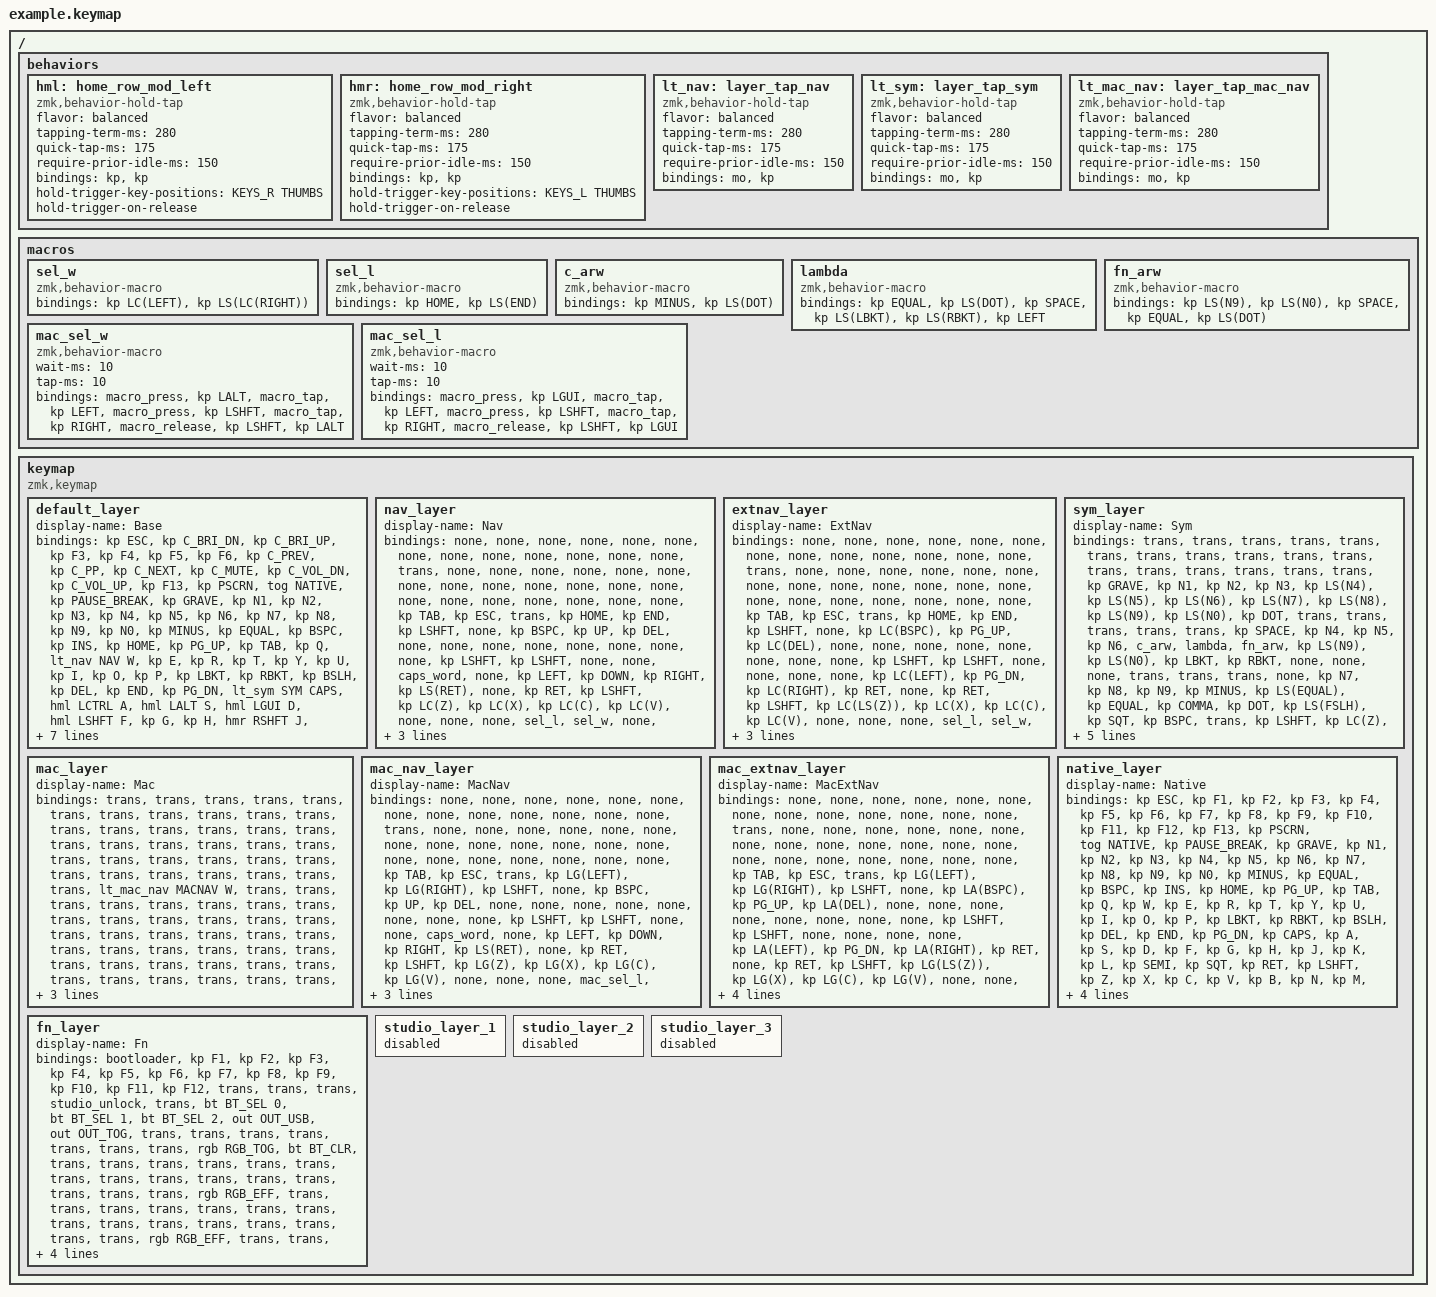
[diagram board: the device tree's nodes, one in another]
/*
 * Wobkey Crush 80 — ZMK keymap (Home Row Mods + Layers)
 *
 * Mirrors the kanata configuration at ~/.config/DOTFILES/keybindings/kanata/
 * Primary target: Linux/Windows (macOS compatible via home row GUI mod)
 *
 * Layer 0: Base — HRM (CAGS), media F-row, W(hold)=Nav, Caps(hold)=Sym, '(hold)=Sym
 * Layer 1: Nav — IJKL arrows, editing (hold W)
 * Layer 2: ExtNav — Word-jump, PgUp/PgDn (hold Space while in Nav)
 * Layer 3: Sym — Numbers left, punctuation right (hold Caps or ')
 * Layer 4-6: Mac / MacNav / MacExtNav — macOS shortcuts, toggled by Fn+M
 * Layer 7: Native — Full passthrough, toggled by ScrLk
 * Layer 8: Fn — F1-F12, BT profiles, RGB, output toggle (top layer)
 * Layer 9-11: reserved, for layers added in ZMK Studio (must stay last)
 *
 * Bottom row (base):
 *   LCtrl  LGui  [Shift]  Space  [Tab]  Fn  RCtrl  |  Left Down Right
 *   LAlt position = Shift (thumb), RAlt position = Tab (thumb)
 *
 * Fn shortcuts:
 *   BT profile 1/2/3 = Fn+1/2/3
 *   USB output = Fn+4, USB/BT toggle = Fn+5
 *   BT clear = Fn+Ins
 *   Bootloader = Fn+Esc, ZMK Studio unlock = Fn+Pause
 */

/* Build every ZMK behavior, not only the ones this file references, so that
 * ZMK Studio and VIA can assign them (&to, &lt, &mt, &sk, ...). The
 * studio-rpc-usb-uart snippet normally defines this; the Bluetooth Studio
 * transport used here does not. Must come before behaviors.dtsi. */
#define ZMK_BEHAVIORS_KEEP_ALL

#include <behaviors.dtsi>
#include <dt-bindings/zmk/keys.h>
#include <dt-bindings/zmk/bt.h>
#include <dt-bindings/zmk/outputs.h>
#include <dt-bindings/zmk/rgb.h>
#include <rainy_rgb.dtsi>
#include <via_macro.dtsi>
#include <dt-bindings/rainy_rgb.h>

/* Layer indices: the order of the layer nodes in the keymap below. */
#define BASE      0
#define NAV       1
#define EXTNAV    2
#define SYM       3
#define MAC       4
#define MACNAV    5
#define MACEXTNAV 6
#define NATIVE    7
#define FN        8

/*
 * Key position indices for hold-trigger-key-positions (bilateral HRM).
 * Derived from the matrix transform in crush80.dts (88 positions, 0-indexed).
 *
 * Row 0 (F-row):     0-16    (ESC F1-F12 F13 PrtSc ScrLk Pause)
 * Row 1 (numbers):   17-33   (` 1-0 - = Bspc | Ins Home PgUp)
 * Row 2 (QWERTY):    34-50   (Tab Q-P [ ] \ | Del End PgDn)
 * Row 3 (home):      51-63   (Caps A-L ; ' Enter)
 * Row 4 (shift):     64-76   (LSft Z-/ RSft Up)
 * Row 5 (bottom):    77-87   (LCtl LGui LAlt Spc RAlt Fn RGui RCtl | Left Down Right)
 */

/* Left hand: up to the T / G / B / 5 / F5 column */
#define KEYS_L \
    0  1  2  3  4  5 \
    17 18 19 20 21 22 \
    34 35 36 37 38 39 \
    51 52 53 54 55 56 \
    64 65 66 67 68 69 \
    77 78

/* Right hand: from the Y / H / N / 6 / F6 column, plus nav cluster and arrows */
#define KEYS_R \
    6  7  8  9  10 11 12 13 14 15 16 \
    23 24 25 26 27 28 29 30 31 32 33 \
    40 41 42 43 44 45 46 47 48 49 50 \
    57 58 59 60 61 62 63 \
    70 71 72 73 74 75 76 \
    82 83 84 85 86 87

/* Thumb keys: LAlt position, Space, RAlt position */
#define THUMBS 79 80 81

/ {
	behaviors {
		/*
		 * Home Row Mods — left hand.
		 * Only triggers hold when a right-hand key is pressed.
		 */
		hml: home_row_mod_left {
			compatible = "zmk,behavior-hold-tap";
			#binding-cells = <2>;
			flavor = "balanced";
			tapping-term-ms = <280>;
			quick-tap-ms = <175>;
			require-prior-idle-ms = <150>;
			bindings = <&kp>, <&kp>;
			hold-trigger-key-positions = <KEYS_R THUMBS>;
			hold-trigger-on-release;
		};

		/*
		 * Home Row Mods — right hand.
		 * Only triggers hold when a left-hand key is pressed.
		 */
		hmr: home_row_mod_right {
			compatible = "zmk,behavior-hold-tap";
			#binding-cells = <2>;
			flavor = "balanced";
			tapping-term-ms = <280>;
			quick-tap-ms = <175>;
			require-prior-idle-ms = <150>;
			bindings = <&kp>, <&kp>;
			hold-trigger-key-positions = <KEYS_L THUMBS>;
			hold-trigger-on-release;
		};

		/*
		 * Layer-tap for Nav (hold W).
		 * Uses balanced flavor with same timings as HRM.
		 */
		lt_nav: layer_tap_nav {
			compatible = "zmk,behavior-hold-tap";
			#binding-cells = <2>;
			flavor = "balanced";
			tapping-term-ms = <280>;
			quick-tap-ms = <175>;
			require-prior-idle-ms = <150>;
			bindings = <&mo>, <&kp>;
		};

		/*
		 * Layer-tap for Sym (hold Caps or Apostrophe).
		 * Caps: tap=CAPS, hold=Sym. Apostrophe: tap=SQT, hold=Sym.
		 */
		lt_sym: layer_tap_sym {
			compatible = "zmk,behavior-hold-tap";
			#binding-cells = <2>;
			flavor = "balanced";
			tapping-term-ms = <280>;
			quick-tap-ms = <175>;
			require-prior-idle-ms = <150>;
			bindings = <&mo>, <&kp>;
		};

		/*
		 * Layer-tap for MacNav (hold W in Mac mode).
		 * Same timings as lt_nav but activates MACNAV.
		 */
		lt_mac_nav: layer_tap_mac_nav {
			compatible = "zmk,behavior-hold-tap";
			#binding-cells = <2>;
			flavor = "balanced";
			tapping-term-ms = <280>;
			quick-tap-ms = <175>;
			require-prior-idle-ms = <150>;
			bindings = <&mo>, <&kp>;
		};
	};

	macros {
		/*
		 * Select Word: Ctrl+Left then Shift+Ctrl+Right (Linux/Windows)
		 */
		sel_w: sel_w {
			compatible = "zmk,behavior-macro";
			#binding-cells = <0>;
			bindings = <&kp LC(LEFT) &kp LS(LC(RIGHT))>;
		};

		/*
		 * Select Line: Home then Shift+End (Linux/Windows)
		 */
		sel_l: sel_l {
			compatible = "zmk,behavior-macro";
			#binding-cells = <0>;
			bindings = <&kp HOME &kp LS(END)>;
		};

		/*
		 * C-style arrow: ->
		 */
		c_arw: c_arw {
			compatible = "zmk,behavior-macro";
			#binding-cells = <0>;
			bindings = <&kp MINUS &kp LS(DOT)>;
		};

		/*
		 * Lambda body: => {} with cursor inside braces
		 */
		lambda: lambda {
			compatible = "zmk,behavior-macro";
			#binding-cells = <0>;
			bindings = <&kp EQUAL &kp LS(DOT) &kp SPACE &kp LS(LBKT) &kp LS(RBKT) &kp LEFT>;
		};

		/*
		 * Arrow function start: () =>
		 */
		fn_arw: fn_arw {
			compatible = "zmk,behavior-macro";
			#binding-cells = <0>;
			bindings = <&kp LS(N9) &kp LS(N0) &kp SPACE &kp EQUAL &kp LS(DOT)>;
		};

		/*
		 * Mac Select Word: Option+Left then Shift+Option+Right
		 */
		mac_sel_w: mac_sel_w {
			compatible = "zmk,behavior-macro";
			#binding-cells = <0>;
			wait-ms = <10>;
			tap-ms = <10>;
			bindings
				= <&macro_press &kp LALT>
				, <&macro_tap &kp LEFT>
				, <&macro_press &kp LSHFT>
				, <&macro_tap &kp RIGHT>
				, <&macro_release &kp LSHFT &kp LALT>
				;
		};

		/*
		 * Mac Select Line: Cmd+Left then Shift+Cmd+Right
		 */
		mac_sel_l: mac_sel_l {
			compatible = "zmk,behavior-macro";
			#binding-cells = <0>;
			wait-ms = <10>;
			tap-ms = <10>;
			bindings
				= <&macro_press &kp LGUI>
				, <&macro_tap &kp LEFT>
				, <&macro_press &kp LSHFT>
				, <&macro_tap &kp RIGHT>
				, <&macro_release &kp LSHFT &kp LGUI>
				;
		};
	};

	keymap {
		compatible = "zmk,keymap";

		/*
		 * Layer 0: Base
		 *
		 * ┌───┬───┬───┬───┬───┬───┬───┬───┬───┬───┬───┬───┬───┬───┬───┬───┐
		 * │ESC│BDn│BUp│F3 │F4 │F5 │F6 │Prv│P/P│Nxt│Mut│VDn│VUp│PSc│Tog│Pse│
		 * ├───┼───┼───┼───┼───┼───┼───┼───┼───┼───┼───┼───┼───┼───┼───┼───┤
		 * │ ` │ 1 │ 2 │ 3 │ 4 │ 5 │ 6 │ 7 │ 8 │ 9 │ 0 │ - │ = │Bsp│Ins│Hom│PUp│
		 * ├───┼───┼───┼───┼───┼───┼───┼───┼───┼───┼───┼───┼───┼───┼───┼───┤
		 * │Tab│ Q │W/N│ E │ R │ T │ Y │ U │ I │ O │ P │ [ │ ] │ \ │Del│End│PDn│
		 * ├───┼───┼───┼───┼───┼───┼───┼───┼───┼───┼───┼───┼───┼───┼───┼───┤
		 * │Sym│A/C│S/A│D/G│F/S│ G │ H │J/S│K/G│L/A│;/C│Sym│Ent│
		 * ├───┼───┼───┼───┼───┼───┼───┼───┼───┼───┼───┼───┼───────┼───┤
		 * │LSf│ Z │ X │ C │ V │ B │ N │ M │ , │ . │ / │RSf│ ↑ │
		 * ├───┼───┼───┼───────────────────────────┼───┼───┼───┼───┼───┼───┤
		 * │LCt│LGu│Sft│      Space       │Tab│ Fn│RCt│ ← │ ↓ │ → │
		 * └───┴───┴───┴───────────────────┴───┴───┴───┴───┴───┴───┘
		 */
		default_layer {
			display-name = "Base";
			bindings = <
				/* Row 0: F-row (media keys, ScrLk=toggle native) */
				&kp ESC       &kp C_BRI_DN  &kp C_BRI_UP  &kp F3        &kp F4
				&kp F5        &kp F6        &kp C_PREV    &kp C_PP
				&kp C_NEXT    &kp C_MUTE    &kp C_VOL_DN  &kp C_VOL_UP  &kp F13
				&kp PSCRN     &tog NATIVE   &kp PAUSE_BREAK
				/* Row 1: number row + nav cluster */
				&kp GRAVE     &kp N1        &kp N2        &kp N3        &kp N4
				&kp N5        &kp N6        &kp N7        &kp N8        &kp N9
				&kp N0        &kp MINUS     &kp EQUAL     &kp BSPC
				&kp INS       &kp HOME      &kp PG_UP
				/* Row 2: QWERTY + nav cluster (W = tap W / hold Nav) */
				&kp TAB       &kp Q         &lt_nav NAV W &kp E         &kp R
				&kp T         &kp Y         &kp U         &kp I         &kp O
				&kp P         &kp LBKT      &kp RBKT      &kp BSLH
				&kp DEL       &kp END       &kp PG_DN
				/* Row 3: home row (HRM: A=Ctrl, S=Alt, D=Gui, F=Shift / J=Shift, K=Gui, L=Alt, ;=Ctrl) */
				&lt_sym SYM CAPS &hml LCTRL A &hml LALT S &hml LGUI D &hml LSHFT F
				&kp G         &kp H         &hmr RSHFT J  &hmr RGUI K   &hmr RALT L
				&hmr RCTRL SEMI &lt_sym SYM SQT           &kp RET
				/* Row 4: shift row */
				&kp LSHFT                   &kp Z         &kp X         &kp C
				&kp V         &kp B         &kp N         &kp M         &kp COMMA
				&kp DOT       &kp FSLH                    &kp RSHFT     &kp UP
				/* Row 5: bottom row (LAlt=Shift, RAlt=Tab) */
				&kp LCTRL     &kp LGUI      &kp LSHFT                   &kp SPACE
				&kp TAB       &mo FN  &kp RGUI        &kp RCTRL
				&kp LEFT      &kp DOWN      &kp RIGHT
			>;
		};

		/*
		 * Layer 1: Nav (hold W)
		 * Right hand: IJKL arrows, U=Bspc, O=Del, ;=Shift+Enter
		 * Left hand: editing (Undo/Cut/Copy/Paste), E=Home, R=End, T/A/S=Shift
		 * G = Caps Word (auto-deactivates on space/punctuation)
		 */
		nav_layer {
			display-name = "Nav";
			bindings = <
				/* Row 0: blocked */
				&none         &none         &none         &none         &none
				&none         &none         &none         &none
				&none         &none         &none         &none  &trans
				&none         &none         &none
				/* Row 1: blocked */
				&none         &none         &none         &none         &none
				&none         &none         &none         &none         &none
				&none         &none         &none         &none
				&none         &none         &none
				/* Row 2: Tab, Esc, (W held), Home, End, Shift, _, Bspc, Up, Del */
				&kp TAB       &kp ESC       &trans        &kp HOME      &kp END
				&kp LSHFT     &none         &kp BSPC      &kp UP        &kp DEL
				&none         &none         &none         &none
				&none         &none         &none
				/* Row 3: _, Shift, Shift, _, _, CapsWord, _, Left, Down, Right, Shift+Enter */
				&none         &kp LSHFT     &kp LSHFT     &none         &none
				&caps_word    &none         &kp LEFT      &kp DOWN      &kp RIGHT
				&kp LS(RET)   &none                       &kp RET
				/* Row 4: Shift, Undo, Cut, Copy, Paste, _, _, _, SelLine, SelWord */
				&kp LSHFT                   &kp LC(Z)     &kp LC(X)     &kp LC(C)
				&kp LC(V)     &none         &none         &none         &sel_l
				&sel_w        &none                       &kp RSHFT     &trans
				/* Row 5: pass mods through, Space=ExtNav */
				&kp LCTRL     &kp LGUI      &kp LALT                    &mo EXTNAV
				&trans        &trans  &trans        &kp RCTRL
				&trans        &trans        &trans
			>;
		};

		/*
		 * Layer 2: ExtNav (hold Space while in Nav)
		 * Like Nav but word-level: J/L=word jump, I=PgUp, K=PgDn, U/O=word delete
		 * Z=Redo (Ctrl+Shift+Z on Linux/Win)
		 */
		extnav_layer {
			display-name = "ExtNav";
			bindings = <
				/* Row 0: blocked */
				&none         &none         &none         &none         &none
				&none         &none         &none         &none
				&none         &none         &none         &none  &trans
				&none         &none         &none
				/* Row 1: blocked */
				&none         &none         &none         &none         &none
				&none         &none         &none         &none         &none
				&none         &none         &none         &none
				&none         &none         &none
				/* Row 2: Tab, Esc, _, Home, End, Shift, _, WordBspc, PgUp, WordDel */
				&kp TAB       &kp ESC       &trans        &kp HOME      &kp END
				&kp LSHFT     &none         &kp LC(BSPC)  &kp PG_UP     &kp LC(DEL)
				&none         &none         &none         &none
				&none         &none         &none
				/* Row 3: _, Shift, Shift, _, _, _, _, WordLeft, PgDn, WordRight, Enter */
				&none         &kp LSHFT     &kp LSHFT     &none         &none
				&none         &none         &kp LC(LEFT)  &kp PG_DN     &kp LC(RIGHT)
				&kp RET       &none                       &kp RET
				/* Row 4: Shift, Redo, Cut, Copy, Paste, _, _, _, SelLine, SelWord */
				&kp LSHFT                   &kp LC(LS(Z)) &kp LC(X)     &kp LC(C)
				&kp LC(V)     &none         &none         &none         &sel_l
				&sel_w        &none                       &kp RSHFT     &trans
				/* Row 5: mods pass through, Space is held (layer active) */
				&kp LCTRL     &kp LGUI      &kp LALT                    &none
				&trans        &trans  &trans        &kp RCTRL
				&trans        &trans        &trans
			>;
		};

		/*
		 * Layer 3: Sym (hold Caps or Apostrophe)
		 * Left: numbers (456 top, 789 home, 0. bottom) + coding macros
		 * Right: brackets, punctuation, operators
		 * Space = Shift (for capitals without releasing layer key)
		 */
		sym_layer {
			display-name = "Sym";
			bindings = <
				/* Row 0: pass through */
				&trans        &trans        &trans        &trans        &trans
				&trans        &trans        &trans        &trans
				&trans        &trans        &trans        &trans  &trans
				&trans        &trans        &trans
				/* Row 1: number row symbols (` 1 2 3 $ % ^ & * ( ) . = _) */
				&kp GRAVE     &kp N1        &kp N2        &kp N3        &kp LS(N4)
				&kp LS(N5)    &kp LS(N6)    &kp LS(N7)    &kp LS(N8)    &kp LS(N9)
				&kp LS(N0)    &kp DOT       &trans        &trans
				&trans        &trans        &trans
				/* Row 2: left=4,5,6,->,lambda | right=() =>, (, ), [, ] */
				&kp SPACE     &kp N4        &kp N5        &kp N6        &c_arw
				&lambda       &fn_arw       &kp LS(N9)    &kp LS(N0)    &kp LBKT
				&kp RBKT      &none         &none         &none
				&trans        &trans        &trans
				/* Row 3: left=_,7,8,9,-,+ | right==,comma,dot,?,',bspc */
				&none         &kp N7        &kp N8        &kp N9        &kp MINUS
				&kp LS(EQUAL) &kp EQUAL     &kp COMMA     &kp DOT       &kp LS(FSLH)
				&kp SQT       &kp BSPC                    &trans
				/* Row 4: Shift, Undo, 0, dot, \, |, /, _, _, _, _ */
				&kp LSHFT                   &kp LC(Z)     &kp N0        &kp DOT
				&kp BSLH      &kp LS(BSLH)  &kp FSLH      &none         &none
				&none         &none                       &kp RSHFT     &trans
				/* Row 5: pass mods, Space=Shift, right thumb=0,dot */
				&kp LCTRL     &kp LGUI      &trans                      &kp LSHFT
				&kp N0        &kp DOT  &trans       &kp RCTRL
				&trans        &trans        &trans
			>;
		};

		/*
		 * Layer 4: Mac (toggle Fn+M)
		 * Transparent: same as Base except W-hold activates MacNav instead of Nav.
		 * (Must stay transparent, or it hides Base's HRM and Sym keys.)
		 */
		mac_layer {
			display-name = "Mac";
			bindings = <
				/* Row 0 */
				&trans        &trans        &trans        &trans        &trans
				&trans        &trans        &trans        &trans        &trans
				&trans        &trans        &trans  &trans        &trans        &trans
				&trans
				/* Row 1 */
				&trans        &trans        &trans        &trans        &trans
				&trans        &trans        &trans        &trans        &trans
				&trans        &trans        &trans        &trans        &trans
				&trans        &trans
				/* Row 2: only W-hold differs (MacNav) */
				&trans        &trans        &lt_mac_nav MACNAV W  &trans        &trans
				&trans        &trans        &trans        &trans        &trans
				&trans        &trans        &trans        &trans        &trans
				&trans        &trans
				/* Row 3 */
				&trans        &trans        &trans        &trans        &trans
				&trans        &trans        &trans        &trans        &trans
				&trans        &trans        &trans
				/* Row 4 */
				&trans        &trans        &trans        &trans        &trans
				&trans        &trans        &trans        &trans        &trans
				&trans        &trans        &trans
				/* Row 5 */
				&trans        &trans        &trans        &trans        &trans
				&trans  &trans        &trans        &trans        &trans        &trans
			>;
		};

		/*
		 * Layer 5: MacNav (hold W in Mac mode)
		 * Same as Nav but with macOS shortcuts:
		 *   Home/End → Cmd+Left/Right, Cut/Copy/Paste → Cmd+X/C/V
		 *   Select Word/Line → Option/Cmd macros
		 */
		mac_nav_layer {
			display-name = "MacNav";
			bindings = <
				/* Row 0: blocked */
				&none         &none         &none         &none         &none
				&none         &none         &none         &none
				&none         &none         &none         &none  &trans
				&none         &none         &none
				/* Row 1: blocked */
				&none         &none         &none         &none         &none
				&none         &none         &none         &none         &none
				&none         &none         &none         &none
				&none         &none         &none
				/* Row 2: Tab, Esc, (W held), Cmd+Left, Cmd+Right, Shift */
				&kp TAB       &kp ESC       &trans        &kp LG(LEFT)  &kp LG(RIGHT)
				&kp LSHFT     &none         &kp BSPC      &kp UP        &kp DEL
				&none         &none         &none         &none
				&none         &none         &none
				/* Row 3: _, Shift, Shift, _, _, CapsWord, _, Left, Down, Right, Shift+Enter */
				&none         &kp LSHFT     &kp LSHFT     &none         &none
				&caps_word    &none         &kp LEFT      &kp DOWN      &kp RIGHT
				&kp LS(RET)   &none                       &kp RET
				/* Row 4: Shift, Cmd+Z, Cmd+X, Cmd+C, Cmd+V, _, _, _, MacSelLine, MacSelWord */
				&kp LSHFT                   &kp LG(Z)     &kp LG(X)     &kp LG(C)
				&kp LG(V)     &none         &none         &none         &mac_sel_l
				&mac_sel_w    &none                       &kp RSHFT     &trans
				/* Row 5: pass mods through, Space=MacExtNav */
				&kp LCTRL     &kp LGUI      &kp LALT                    &mo MACEXTNAV
				&trans        &trans  &trans        &kp RCTRL
				&trans        &trans        &trans
			>;
		};

		/*
		 * Layer 6: MacExtNav (hold Space while in MacNav)
		 * Same as ExtNav but with macOS shortcuts:
		 *   Word jump → Option+Arrow, Word delete → Option+Bspc/Del
		 *   Redo → Cmd+Shift+Z
		 */
		mac_extnav_layer {
			display-name = "MacExtNav";
			bindings = <
				/* Row 0: blocked */
				&none         &none         &none         &none         &none
				&none         &none         &none         &none
				&none         &none         &none         &none  &trans
				&none         &none         &none
				/* Row 1: blocked */
				&none         &none         &none         &none         &none
				&none         &none         &none         &none         &none
				&none         &none         &none         &none
				&none         &none         &none
				/* Row 2: Tab, Esc, _, Cmd+Left, Cmd+Right, Shift, _, Opt+Bspc, PgUp, Opt+Del */
				&kp TAB       &kp ESC       &trans        &kp LG(LEFT)  &kp LG(RIGHT)
				&kp LSHFT     &none         &kp LA(BSPC)  &kp PG_UP     &kp LA(DEL)
				&none         &none         &none         &none
				&none         &none         &none
				/* Row 3: _, Shift, Shift, _, _, _, _, Opt+Left, PgDn, Opt+Right, Enter */
				&none         &kp LSHFT     &kp LSHFT     &none         &none
				&none         &none         &kp LA(LEFT)  &kp PG_DN     &kp LA(RIGHT)
				&kp RET       &none                       &kp RET
				/* Row 4: Shift, Cmd+Shift+Z, Cmd+X, Cmd+C, Cmd+V, _, _, _, MacSelLine, MacSelWord */
				&kp LSHFT                   &kp LG(LS(Z)) &kp LG(X)     &kp LG(C)
				&kp LG(V)     &none         &none         &none         &mac_sel_l
				&mac_sel_w    &none                       &kp RSHFT     &trans
				/* Row 5: mods pass through, Space is held (layer active) */
				&kp LCTRL     &kp LGUI      &kp LALT                    &none
				&trans        &trans  &trans        &kp RCTRL
				&trans        &trans        &trans
			>;
		};

		/*
		 * Layer 7: Native (full passthrough — no remapping)
		 * Toggle on/off with ScrLk (tog NATIVE in Base and here). Sits above
		 * the Mac layers so it also bypasses Mac mode.
		 */
		native_layer {
			display-name = "Native";
			bindings = <
				/* Row 0: standard F-row, ScrLk position toggles back to base */
				&kp ESC       &kp F1        &kp F2        &kp F3        &kp F4
				&kp F5        &kp F6        &kp F7        &kp F8
				&kp F9        &kp F10       &kp F11       &kp F12  &kp F13
				&kp PSCRN     &tog NATIVE   &kp PAUSE_BREAK
				/* Row 1: standard number row */
				&kp GRAVE     &kp N1        &kp N2        &kp N3        &kp N4
				&kp N5        &kp N6        &kp N7        &kp N8        &kp N9
				&kp N0        &kp MINUS     &kp EQUAL     &kp BSPC
				&kp INS       &kp HOME      &kp PG_UP
				/* Row 2: standard QWERTY */
				&kp TAB       &kp Q         &kp W         &kp E         &kp R
				&kp T         &kp Y         &kp U         &kp I         &kp O
				&kp P         &kp LBKT      &kp RBKT      &kp BSLH
				&kp DEL       &kp END       &kp PG_DN
				/* Row 3: standard home row */
				&kp CAPS      &kp A         &kp S         &kp D         &kp F
				&kp G         &kp H         &kp J         &kp K         &kp L
				&kp SEMI      &kp SQT                     &kp RET
				/* Row 4: standard shift row */
				&kp LSHFT                   &kp Z         &kp X         &kp C
				&kp V         &kp B         &kp N         &kp M         &kp COMMA
				&kp DOT       &kp FSLH                    &kp RSHFT     &kp UP
				/* Row 5: standard bottom row */
				&kp LCTRL     &kp LGUI      &kp LALT                    &kp SPACE
				&kp RALT      &mo FN  &kp RGUI        &kp RCTRL
				&kp LEFT      &kp DOWN      &kp RIGHT
			>;
		};

		/*
		 * Layer 8: Fn — must stay the highest real layer. ZMK resolves a
		 * key from the highest active layer down, so any layer above Fn that
		 * binds a key (Mac, Native) would swallow that Fn shortcut, including
		 * Fn+M, the only way back out of Mac mode.
		 * F-row = actual F1-F12. BT/RGB controls on specific keys.
		 */
		fn_layer {
			display-name = "Fn";
			bindings = <
				/* Row 0: Fn+Esc=bootloader, actual F1-F12, Fn+Pause=Studio unlock */
				&bootloader   &kp F1        &kp F2        &kp F3        &kp F4
				&kp F5        &kp F6        &kp F7        &kp F8
				&kp F9        &kp F10       &kp F11       &kp F12  &trans
				&trans        &trans        &studio_unlock
				/* Row 1: Fn+Bspc=RGB toggle, Fn+Ins=BT clear */
				&trans        &bt BT_SEL 0  &bt BT_SEL 1  &bt BT_SEL 2  &out OUT_USB
				&out OUT_TOG  &trans        &trans        &trans        &trans
				&trans        &trans        &trans        &rgb RGB_TOG
				&bt BT_CLR    &trans        &trans
				/* Row 2: Fn+\=RGB effect */
				&trans        &trans        &trans        &trans        &trans
				&trans        &trans        &trans        &trans        &trans
				&trans        &trans        &trans        &rgb RGB_EFF
				&trans        &trans        &trans
				/* Row 3: Fn+Enter=RGB effect cycle */
				&trans        &trans        &trans        &trans        &trans
				&trans        &trans        &trans        &trans        &trans
				&trans        &trans                      &rgb RGB_EFF
			/* Row 4: Fn+M=toggle Mac, Fn+Up=RGB bright up */
			&trans                      &trans        &trans        &trans
			&trans        &trans        &trans        &tog MAC      &trans
			&trans        &trans                      &trans        &rgb RGB_BRI
				/* Row 5: Fn+Down=RGB bright down */
				&trans        &trans        &trans                      &trans
				&trans        &trans  &trans        &trans
				&trans        &rgb RGB_BRD &trans
			>;
		};

		/* Layers 9-11: empty slots that ZMK Studio can turn into new layers.
		 * They must come after every real layer: ZMK numbers the enabled
		 * layers first, so a real layer placed after a reserved one is never
		 * looked up (this once killed Fn entirely). */
		studio_layer_1 {
			status = "reserved";
		};

		studio_layer_2 {
			status = "reserved";
		};

		studio_layer_3 {
			status = "reserved";
		};
	};
};
